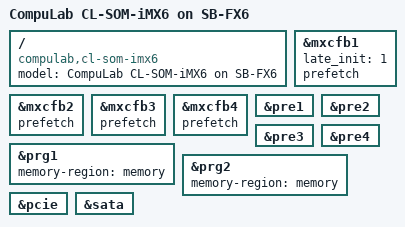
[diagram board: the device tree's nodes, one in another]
/*
* Copyright 2016 CompuLab Ltd.
*
* Author: Valentin Raevsky <valentin@compulab.co.il>
*
* The code contained herein is licensed under the GNU General Public
* License. You may obtain a copy of the GNU General Public License
* Version 2 or later at the following locations:
*
* http://www.opensource.org/licenses/gpl-license.html
* http://www.gnu.org/copyleft/gpl.html
*/

/dts-v1/;
#include "imx6q.dtsi"
#include "imx6q-cl-som-imx6.dtsi"
#include "imx6q-cm-fx6.dtsi"
#include "imx6qdl-sb-fx6x.dtsi"
#include "imx6qdl-sb-fx6.dtsi"
#include "imx6qp.dtsi"

/ {
	model = "CompuLab CL-SOM-iMX6 on SB-FX6";
	compatible = "compulab,cl-som-imx6", "compulab,cm-fx6", "compulab,sbc-imx6", "compulab,sb-fx6", "fsl,imx6qp";
};

&mxcfb1 {
	late_init = <1>;
	prefetch;
};

&mxcfb2 {
	prefetch;
};

&mxcfb3 {
	prefetch;
};

&mxcfb4 {
	prefetch;
};

&pre1 {
	status = "okay";
};

&pre2 {
	status = "okay";
};

&pre3 {
	status = "okay";
};

&pre4 {
	status = "okay";
};

&prg1 {
	memory-region = <&memory>;
	status = "okay";
};

&prg2 {
	memory-region = <&memory>;
	status = "okay";
};

&pcie {
	status = "okay";
};

&sata {
	status = "okay";
};
